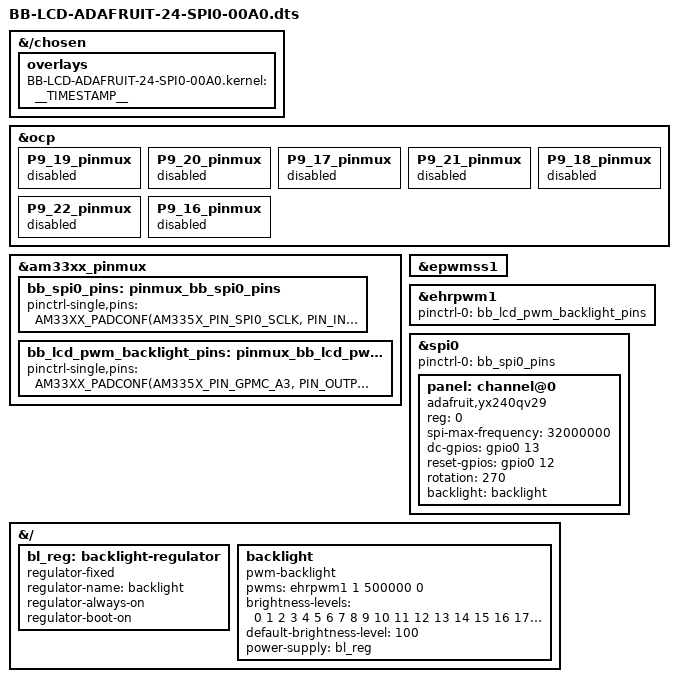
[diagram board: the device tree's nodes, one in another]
// SPDX-License-Identifier: GPL-2.0-only
/*
 * Copyright (C) 2013 CircuitCo
 * Copyright (C) 2018 Drew Fustini <drew@beagleboard.org>
 * Copyright (C) 2019 Mark A. Yoder <mark.a.yoder@beagleboard.org>
 *
 * Adafruit 2.4" TFT LCD on SPI0 bus using tinydrm ili9341 driver
 *
 * DOCUMENTATION:
 * --------------
 * This file was copied from src/arm/BB-SPIDEV1-00A0.dts and modified
 * by Drew Fustini based on an exmample from David Lechner.
 * Later modified by Mark A. Yoder for the 2.4" LCD.
 *
 * This is the Adafruit 2.4" TFT LCD:
 * https://www.adafruit.com/product/2478
 *
 * It should be connected to BeagleBone SPI0 bus:
 *
 *   P9.16 <--> lite (pwm)
 *   P9.17 <--> tft_cs
 *   P9.18 <--> mosi
 *   P9.19 <--> dc
 *   P9.20 <--> reset
 *   P9.21 <--> miso
 *   P9.22 <--> clk
 *
 * This overlay will load the mainline tinydrm ili9341 driver by David Lechner:
 * https://github.com/torvalds/linux/blob/master/drivers/gpu/drm/tiny/ili9341.c
 *
 * Tested with 4.19.59-ti-r26 kernel on Debian 10.1 image
 *
 * Run libdrm modetest for colorbar test based on instructions from:
 * https://github.com/notro/tinydrm/wiki/Development#modetest
 *
 * modetest -M "ili9341" -c #this will display connector id
 * modetest -M "ili9341" -s 28:128x160 #connector id and resolution
 * # you should now see a color bar on the LCD
 *
 * Mailing list post with more information:
 * https://groups.google.com/d/msg/beagleboard/GuMQIP_XCW0/b3lxbx_8AwAJ
 *
 * Discussion with notro on how to test tinydrm driver:
 * https://github.com/notro/tinydrm/issues/1#issuecomment-367279037
 */

/dts-v1/;
/plugin/;

#include <dt-bindings/gpio/gpio.h>
#include <dt-bindings/pinctrl/am33xx.h>
#include <dt-bindings/interrupt-controller/irq.h>

/*
 * Helper to show loaded overlays under: /proc/device-tree/chosen/overlays/
 */
&{/chosen} {
	overlays {
		BB-LCD-ADAFRUIT-24-SPI0-00A0.kernel = __TIMESTAMP__;
	};
};

/*
 * Free up the pins used by the cape from the pinmux helpers.
 */
&ocp {
	P9_19_pinmux { status = "disabled"; };	/* lcd dc */
	P9_20_pinmux { status = "disabled"; };	/* lcd reset */
	P9_17_pinmux { status = "disabled"; };	/* spi0_cs0 */
	P9_21_pinmux { status = "disabled"; };	/* spi0_d0 */
	P9_18_pinmux { status = "disabled"; };	/* spi0_d1 */
	P9_22_pinmux { status = "disabled"; };	/* spi0_sclk */
	P9_16_pinmux { status = "disabled"; };  /* lcd pwm backlight */
};

&am33xx_pinmux {
	bb_spi0_pins: pinmux_bb_spi0_pins {
		pinctrl-single,pins = <
			AM33XX_PADCONF(AM335X_PIN_SPI0_SCLK, PIN_INPUT, MUX_MODE0)	/* P9_22 (A17) spi0_sclk.spi0_sclk */
			AM33XX_PADCONF(AM335X_PIN_SPI0_D0, PIN_INPUT, MUX_MODE0)	/* P9_21 (B17) spi0_d0.spi0_d0 */
			AM33XX_PADCONF(AM335X_PIN_SPI0_D1, PIN_INPUT, MUX_MODE0)	/* P9_18 (B16) spi0_d1.spi0_d1 */
			AM33XX_PADCONF(AM335X_PIN_SPI0_CS0, PIN_INPUT, MUX_MODE0)	/* P9_17 (A16) spi0_cs0.spi0_cs0 */
			AM33XX_PADCONF(AM335X_PIN_UART1_RTSN, PIN_OUTPUT_PULLUP, MUX_MODE7)	/* gpio, dc,       OUTPUT_PULLUP | MODE07*/
			AM33XX_PADCONF(AM335X_PIN_UART1_CTSN, PIN_OUTPUT_PULLUP, MUX_MODE7)	/* gpio, reset,    OUTPUT_PULLUP | MODE07*/
		>;
	};

	bb_lcd_pwm_backlight_pins: pinmux_bb_lcd_pwm_backlight_pins {
		pinctrl-single,pins = <
			AM33XX_PADCONF(AM335X_PIN_GPMC_A3, PIN_OUTPUT, MUX_MODE6)	 /* gpmc_a2.ehrpwm1b, OMAP_MUX_MODE6 | AM33XX_PIN_OUTPUT */
		>;
	};
};

&epwmss1 {
	status = "okay";
};

&ehrpwm1 {
	pinctrl-names = "default";
	pinctrl-0 = <&bb_lcd_pwm_backlight_pins>;
	status = "okay";
};

&spi0 {
	#address-cells = <1>;
	#size-cells = <0>;

	status = "okay";
	pinctrl-names = "default";
	pinctrl-0 = <&bb_spi0_pins>;

	panel: channel@0{
		status = "okay";
		compatible = "adafruit,yx240qv29", "ilitek,ili9341";
		reg = <0>;
		spi-max-frequency = <32000000>;
		dc-gpios    = <&gpio0 13 0>;   // lcd dc    P9.19 gpio0[13]
		reset-gpios = <&gpio0 12 0>;   // lcd reset P9.20 gpio0[12]
		rotation = <270>;
		backlight = <&backlight>;    // lcd lite  P9.16 gpmc_a2.ehrpwm1b
	};
};

&{/} {
	bl_reg: backlight-regulator {
		compatible = "regulator-fixed";
		regulator-name = "backlight";
		regulator-always-on;
		regulator-boot-on;
	};

	backlight: backlight {
		status = "okay";
		compatible = "pwm-backlight";
		pwms = <&ehrpwm1 1 500000 0>;
		brightness-levels = <
			0  1  2  3  4  5  6  7  8  9
			10 11 12 13 14 15 16 17 18 19
			20 21 22 23 24 25 26 27 28 29
			30 31 32 33 34 35 36 37 38 39
			40 41 42 43 44 45 46 47 48 49
			50 51 52 53 54 55 56 57 58 59
			60 61 62 63 64 65 66 67 68 69
			70 71 72 73 74 75 76 77 78 79
			80 81 82 83 84 85 86 87 88 89
			90 91 92 93 94 95 96 97 98 99
			100
		>;
		default-brightness-level = <100>;
		power-supply = <&bl_reg>;
	};
};
